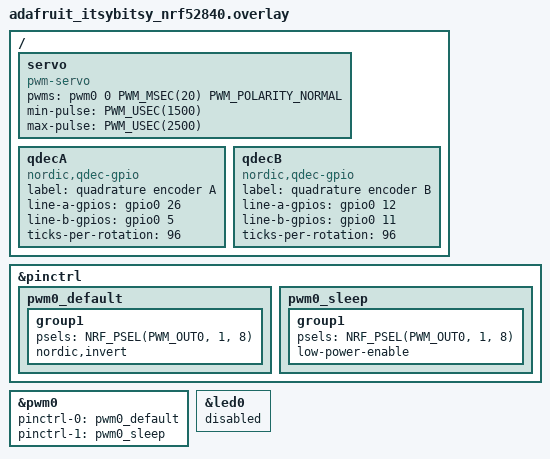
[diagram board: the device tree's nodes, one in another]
/* SPDX-License-Identifier: Apache-2.0 */

/ {
	servo: servo {
		compatible = "pwm-servo";
        status="okay";
		pwms = <&pwm0 0 PWM_MSEC(20) PWM_POLARITY_NORMAL>;
		min-pulse = <PWM_USEC(1500)>;
		max-pulse = <PWM_USEC(2500)>;
	};

	qdecA: qdecA {
		compatible = "nordic,qdec-gpio";
		status = "okay";
		label = "quadrature encoder A";
		line-a-gpios = <&gpio0 26 0>;
		line-b-gpios = <&gpio0 5 0>;
		ticks-per-rotation = <96>;
	};

	qdecB: qdecB {
		compatible = "nordic,qdec-gpio";
		status = "okay";
		label = "quadrature encoder B";
		line-a-gpios = <&gpio0 12 0>;
		line-b-gpios = <&gpio0 11 0>;
		ticks-per-rotation = <96>;
	};

};

&pinctrl {
	
	pwm0_default: pwm0_default {
		group1 {
			psels = <NRF_PSEL(PWM_OUT0, 1, 8)>;
			nordic,invert;
		};
	};

	pwm0_sleep: pwm0_sleep {
		group1 {
			psels = <NRF_PSEL(PWM_OUT0, 1, 8)>;
			low-power-enable;
		};
	};
};


&pwm0 {
	status = "okay";
	pinctrl-0 = <&pwm0_default>;
	pinctrl-1 = <&pwm0_sleep>;
	pinctrl-names = "default", "sleep";
};

&led0 {
    status = "disabled";
};
